# nrf9230_engb_cellrf register map
Vendor: Nordic Semiconductor; Series: nRF92; File version: 1
CPU: CM0 r0p0, little endian, no MPU, no FPU, 2 interrupt priority bits, 33 interrupts
Registers are 32-bit, read-write, reset 0x0 unless marked. A register's access mark holds for its fields unless they carry their own. Offsets are from the block's base; [hi:lo] are bit positions; lines under a group give offsets from that group; {n}, {i} and the like mark numbered series; 'fields as' and 'values as' point back to an identical list.

## BILS — The Built-in Leakage Sensor (BILS) module.
Base 0x46016000
0x400 CONFIG group — Unspecified
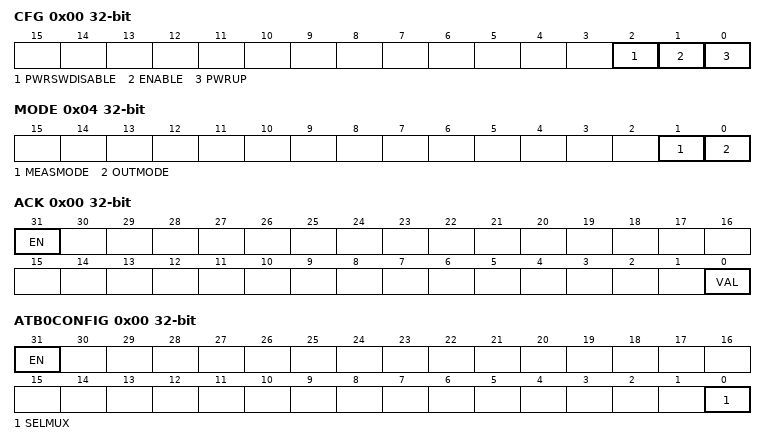
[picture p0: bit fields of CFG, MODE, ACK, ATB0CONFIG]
  0x00 CFG — BILS configuration
    [2] PWRSWDISABLE — Disable power switch.
      0=PwrSwNormalMode (Normal control of the power switch.); 1=PwrSwDisabledMode (Power switch is turned off.)
    [1] ENABLE — BILS enable
      0=BilsDisable (Disable BILS, REQ_SWOFF_AO_0V8 = 0); 1=BilsEnable (Enable BILS, REQ_SWOFF_AO_0V8 is controlled by BILS)
    [0] PWRUP — Power up BILS
      0=PwrOff (BILS is powered down and REQ_SWOFF_AO_0V8=0); 1=PwrOn (BILS is powered up)
  0x04 MODE — Mode selection
    [1] MEASMODE — Measurement mode selection
      0=MeasDisMode (Measure discharge rate); 1=MeasPwMode (Measure power switch chain propagation delay)
    [0] OUTMODE — Output mode selection
      0=Duty50Mode (50:50 duty cycle output selected to FOUT_AO_0V8 pin); 1=CompMode (Comparator output selected to FOUT_AO_0V8 pin)
0x500 OVERRIDE group — Unspecified
  0x00 ACK — Override the ACL_SWOFF_0V8 signal
    [31] EN — Override enable
      0=Disabled (Override disabled); 1=Enabled (Override is enabled)
    [0] VAL — Override value
0x600 DFT group — Unspecified
  0x00 ATB0CONFIG — Analog Test Bus 0 (ATB0) configuration
    [31] EN — Enable the analog test bus
      0=Disabled (Analog test bus is disabled); 1=Enabled (Analog test bus is enabled)
    [0] SELMUX — Select multiplexer for ATB0
      0=None selected; 1=Connect (Voltage on ATB0 used as threshold voltage)
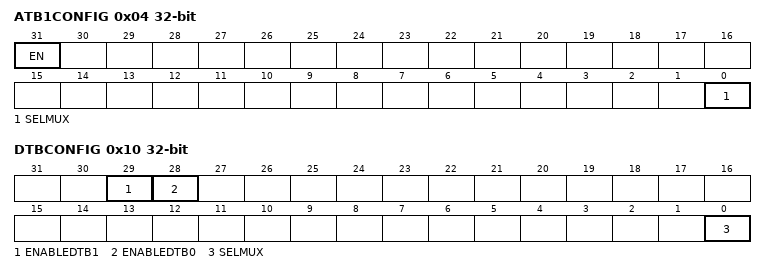
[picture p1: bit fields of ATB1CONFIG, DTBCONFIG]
  0x04 ATB1CONFIG — Analog Test Bus 1 (ATB1) configuration
    [31] EN — Enable the analog test bus
      values as DFT.ATB0CONFIG.EN
    [0] SELMUX — Select multiplexer for ATB1
      0=None selected; 1=ConnectDVDD (ATB1 connected to DVDD_0V8_SW)
  0x10 DTBCONFIG — Digital Test Bus configuration
    [29] ENABLEDTB1 — Enable the digital test bus
      0=Disabled (Digital test bus is disabled); 1=Enabled (Digital test bus is enabled)
    [28] ENABLEDTB0 — Enable the digital test bus
      values as ENABLEDTB1
    [0] SELMUX — Select multiplexer for DTB0
      0=None selected; 1=Connect (FOUT_AO_0V8 is connected to DTB0, REQ_SWOFF_AO_0V8 is connected to DTB1)

## DPPIC — Distributed programmable peripheral interconnect controller
Base 0x46050000
Same registers: GLOBAL_DPPIC120 0x5F8E1000, GLOBAL_DPPIC130 0x5F922000, GLOBAL_DPPIC131 0x5F981000, GLOBAL_DPPIC132 0x5F991000, GLOBAL_DPPIC133 0x5F9A1000, GLOBAL_DPPIC134 0x5F9B1000, GLOBAL_DPPIC135 0x5F9C1000, GLOBAL_DPPIC136 0x5F9D1000
{0x0+8i} TASKS_CHG[{i}] (i=0..3) group — Channel group tasks
  0x00 EN wo — Description cluster: Enable channel group n
    [0] EN — Enable channel group n
      1=Trigger task
  0x04 DIS wo — Description cluster: Disable channel group n
    [0] DIS — Disable channel group n
      1=Trigger task
{0x80+8i} SUBSCRIBE_CHG[{i}] (i=0..3) group — Subscribe configuration for tasks
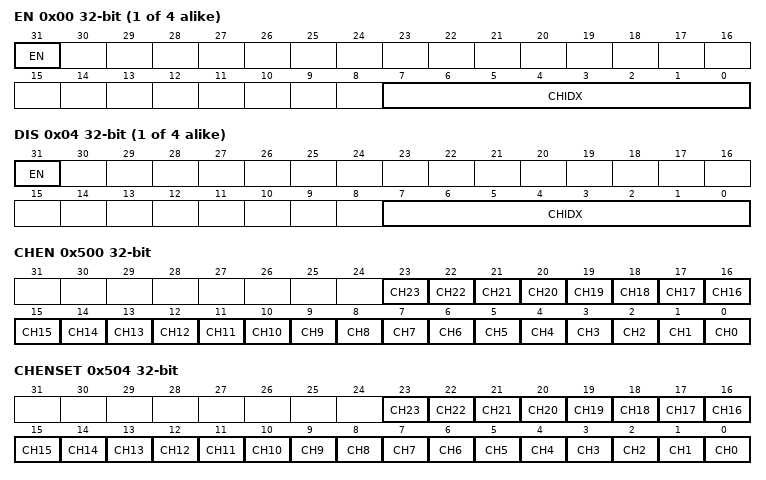
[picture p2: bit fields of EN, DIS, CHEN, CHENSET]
  0x00 EN — Description cluster: Subscribe configuration for task CHG[n].EN
    [31] EN
      0=Disabled (Disable subscription); 1=Enabled (Enable subscription)
    [7:0] CHIDX — DPPI channel that task CHG[n].EN will subscribe to
  0x04 DIS — Description cluster: Subscribe configuration for task CHG[n].DIS
    [31] EN
      values as SUBSCRIBE_CHG[0].EN.EN
    [7:0] CHIDX — DPPI channel that task CHG[n].DIS will subscribe to
0x500 CHEN — Channel enable register
  [all] fields
    0=Disabled (Disable channel); 1=Enabled (Enable channel)
  [n] CH{n} (n=0..23) — Enable or disable channel {n}
0x504 CHENSET write-1-sets — Channel enable set register
  [all] fields
    on read: 0=Disabled (Read: Channel disabled); 1=Enabled (Read: Channel enabled) | on write: 1=Set (Write: Enable channel)
  [n] CH{n} (n=0..23) — Channel {n} enable set register. Writing 0 has no effect.
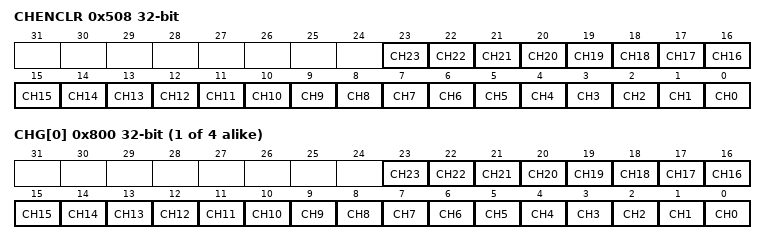
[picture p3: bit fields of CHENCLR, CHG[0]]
0x508 CHENCLR write-1-clears — Channel enable clear register
  [all] fields
    on read: 0=Disabled (Read: Channel disabled); 1=Enabled (Read: Channel enabled) | on write: 1=Clear (Write: Disable channel)
  [n] CH{n} (n=0..23) — Channel {n} enable clear register. Writing 0 has no effect.
{0x800+4i} CHG[{i}] (i=0..3) — Description collection: Channel group n Note: Writes to this register are ignored if either SUBSCRIBE_CHG[n].EN or SUBSCRIBE_CHG[n].DIS is enabled
  [all] fields
    0=Excluded; 1=Included
  [n] CH{n} (n=0..23) — Include or exclude channel {n}

## Notices in the file
Copyright (c) 2010 - 2024, Nordic Semiconductor ASA
All rights reserved.
Redistribution and use in source and binary forms, with or without modification,
are permitted provided that the following conditions are met:
1. Redistributions of source code must retain the above copyright notice, this
list of conditions and the following disclaimer.
2. Redistributions in binary form, except as embedded into a Nordic
Semiconductor ASA integrated circuit in a product or a software update for
such product, must reproduce the above copyright notice, this list of
conditions and the following disclaimer in the documentation and/or other
materials provided with the distribution.
3. Neither the name of Nordic Semiconductor ASA nor the names of its
contributors may be used to endorse or promote products derived from this
software without specific prior written permission.
4. This software, with or without modification, must only be used with a
Nordic Semiconductor ASA integrated circuit.
5. Any software provided in binary form under this license must not be reverse
engineered, decompiled, modified and/or disassembled.
THIS SOFTWARE IS PROVIDED BY NORDIC SEMICONDUCTOR ASA "AS IS" AND ANY EXPRESS
OR IMPLIED WARRANTIES, INCLUDING, BUT NOT LIMITED TO, THE IMPLIED WARRANTIES
OF MERCHANTABILITY, NONINFRINGEMENT, AND FITNESS FOR A PARTICULAR PURPOSE ARE
DISCLAIMED. IN NO EVENT SHALL NORDIC SEMICONDUCTOR ASA OR CONTRIBUTORS BE
LIABLE FOR ANY DIRECT, INDIRECT, INCIDENTAL, SPECIAL, EXEMPLARY, OR
CONSEQUENTIAL DAMAGES (INCLUDING, BUT NOT LIMITED TO, PROCUREMENT OF SUBSTITUTE
GOODS OR SERVICES; LOSS OF USE, DATA, OR PROFITS; OR BUSINESS INTERRUPTION)
HOWEVER CAUSED AND ON ANY THEORY OF LIABILITY, WHETHER IN CONTRACT, STRICT
LIABILITY, OR TORT (INCLUDING NEGLIGENCE OR OTHERWISE) ARISING IN ANY WAY OUT
OF THE USE OF THIS SOFTWARE, EVEN IF ADVISED OF THE POSSIBILITY OF SUCH DAMAGE.
